# H616 register map
Vendor: Allwinner; Series: H616; File version: 0.1
CPU: other 0, little endian, MPU, no FPU, 0 interrupt priority bits
Registers are 32-bit, read-write, reset 0x0 unless marked. A register's access mark holds for its fields unless they carry their own. Offsets are from the block's base; [hi:lo] are bit positions; lines under a group give offsets from that group; {n}, {i} and the like mark numbered series; 'fields as' and 'values as' point back to an identical list; <NAME> marks a mode.

## Audio_Codec
Base 0x05096000
0x00 ANALOG DOMAIN REGISTER group
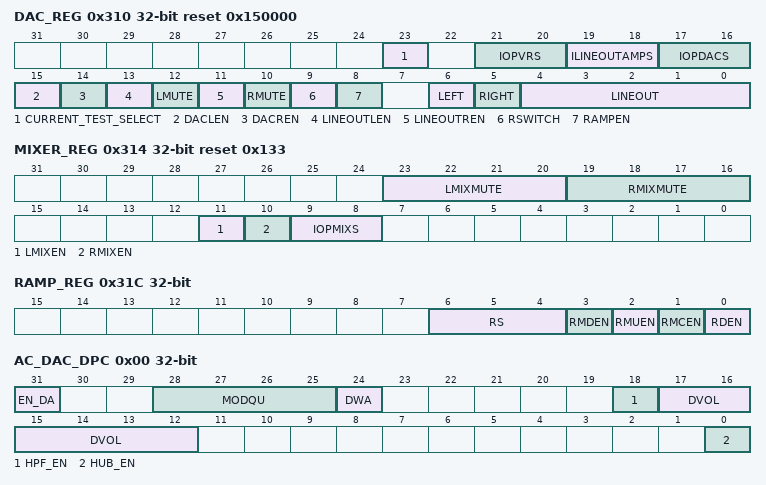
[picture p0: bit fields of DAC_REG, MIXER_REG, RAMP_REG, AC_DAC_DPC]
  0x310 DAC_REG reset 0x150000 — DAC Analog Control Register
    [23] CURRENT_TEST_SELECT — Internal Current Sink Test Enable 0: Normal 1: For Debug
      0=Normal; 1=For (For Debug)
    [21:20] IOPVRS — VRA2 Buffer OP Bias Current Select 00: 6uA 01: 7uA 10: 8uA 11: 9uA
      {v}=_{v+6}uA (v=0..3)
    [19:18] ILINEOUTAMPS — LINEOUTL/R AMP Bias Current Select 00: 6uA 01: 7uA 10: 8uA 11: 9uA
      {v}=_{v+6}uA (v=0..3)
    [17:16] IOPDACS — OPDAC Bias Current Select 00: 7uA 01: 8uA 10: 9uA 11: 10uA
      {v}=_{v+7}uA (v=0..3)
    [15] DACLEN — DACL Enable 0: Disable 1: Enable
      0=Disable; 1=Enable
    [14] DACREN — DACR Enable 0: Disable 1: Enable
      0=Disable; 1=Enable
    [13] LINEOUTLEN — Left Channel LINEOUT Enable 0: Disable 1: Enable
      0=Disable; 1=Enable
    [12] LMUTE — Left MIXER to Left Channel LINEOUT Mute Control 0: Mute 1: Not mute
      0=Mute; 1=Not_mute
    [11] LINEOUTREN — Right Channel LINEOUT Enable 0: Disable 1: Enable
      0=Disable; 1=Enable
    [10] RMUTE — Right MIXER to Right Channel LINEOUT Mute Control 0: Mute 1: Not mute
      0=Mute; 1=Not_mute
    [9] RSWITCH — 0: OUTPUT of RAMP_DAC 1: VRA1
      0=OUTPUT (OUTPUT of RAMP_DAC); 1=VRA1
    [8] RAMPEN — Ramp DAC Enable 0: Disable 1: Enable
      0=Disable; 1=Enable
    [6] LEFT — Left LIENOUT Source Select 0: Left Output Mixer 1: Left Output Mixer + Right Output Mixer
    [5] RIGHT — Right LIENOUT Source Select 0: Right Output Mixer 1: Left LINEOUT, for Differential Output
      0=Right Output Mixer; 1=Left LINEOUT, for Differential Output
    [4:0] LINEOUT — Volume Control, Total 30 level from 0x1F to 0x02 with the volume 0dB to -43.5dB, -1.5dB/step, mute when 00000 & 00001.
  0x314 MIXER_REG reset 0x133 — MIXER Analog Control Register
    [23:20] LMIXMUTE — Left Output Mixer Mute Control 0:Mute, 1:Not Mute Bit 23: Reserved Bit 22: Reserved Bit 21: Left Channel DAC Bit 20: Right Channel DAC
    [19:16] RMIXMUTE — Right Output Mixer Mute Control 0:Mute, 1:Not Mute Bit 19: Reserved Bit 18: Reserved Bit 17: Right Channel DAC Bit 16: Left Channel DAC
    [11] LMIXEN — Left Analog Output Mixer Enable 0: Disable 1: Enable
      0=Disable; 1=Enable
    [10] RMIXEN — Right Analog Output Mixer Enable 0: Disable 1: Enable
      0=Disable; 1=Enable
    [9:8] IOPMIXS — OPMIX/OPLPF Bias Current Select 00: 6uA 01: 7uA 10: 8uA 11: 9uA
      {v}=_{v+6}uA (v=0..3)
  0x31C RAMP_REG — RAMP Control Register
    [6:4] RS — Ramp Step 000: 3us 001: 6us 010: 12us 011: 24us 100: 48us 101: 60us 110: 96us 111: 120us
      0=_3us; 1=_6us; 2=_12us; 3=_24us; 4=_48us; 5=_60us; 6=_96us; 7=_120us
    [3] RMDEN — Ramp Manual Down Enable 0: Disable 1: Enable
      0=Disable; 1=Enable
    [2] RMUEN — Ramp Manual Up Enable 0: Disable 1: Enable
      0=Disable; 1=Enable
    [1] RMCEN — Ramp Manual Control Enable 0: Disable 1: Enable
      0=Disable; 1=Enable
    [0] RDEN — Ramp Digital Enable 0: Disable 1: Enable
      0=Disable; 1=Enable
0x00 AUDIO CODEC group
  0x00 AC_DAC_DPC — DAC Digital Part Control Register
    [31] EN_DA — DAC Digital Part Enable 0: Disable 1: Enable
      0=Disable; 1=Enable
    [28:25] MODQU — Internal DAC Quantization Levels Levels=[7*(21+MODQU[3:0])]/128 Default levels=7*21/128=1.15
    [24] DWA — DWA Function Disable 0: Enable 1: Disable
      0=Enable; 1=Disable
    [18] HPF_EN — High Pass Filter Enable 0: Disable 1: Enable
      0=Disable; 1=Enable
    [17:12] DVOL — Digital volume control: DVC, ATT=DVC[5:0]*(-1.16dB) 64 steps, -1.16dB/step
    [0] HUB_EN — Audio Hub Enable 0: Disable 1: Enable
      0=Disable; 1=Enable
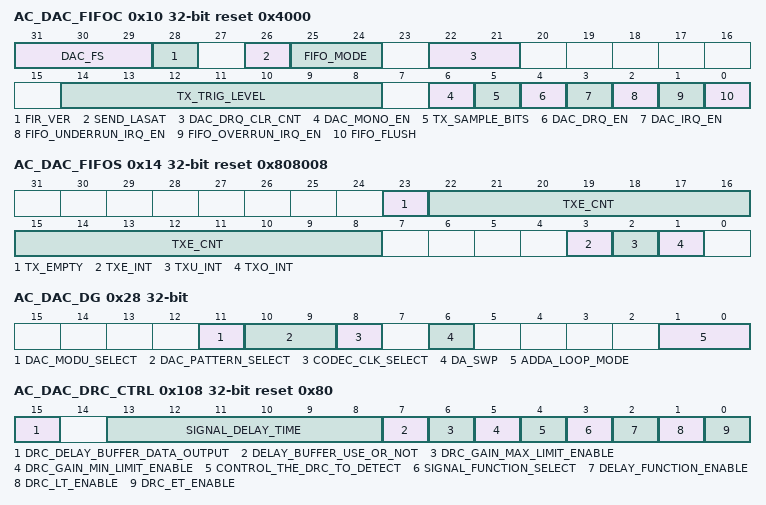
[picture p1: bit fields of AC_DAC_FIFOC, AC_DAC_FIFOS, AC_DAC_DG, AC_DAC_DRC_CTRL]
  0x10 AC_DAC_FIFOC reset 0x4000 — DAC FIFO Control Register
    [31:29] DAC_FS — Sample Rate of DAC 000: 48 kHz 010: 24 kHz 100: 12 kHz 110: 192 kHz 001: 32 kHz 011: 16 kHz 101: 8 kHz 111: 96 kHz 44.1 kHz/22.05 kHz/11.025 kHz can be supported by Audio PLL Configure Bit
      0=_48_kHz; 2=_24_kHz; 4=_12_kHz; 6=_192_kHz; 1=_32_kHz; 3=_16_kHz; 5=_8_kHz; 7=96 kHz 44.1 kHz/22.05 kHz/11.025 kHz can be supported by Audio PLL Configure Bit
    [28] FIR_VER — FIR Version 0: 64-Tap FIR 1: 32-Tap FIR
      0=_64_minus_Tap (64-Tap FIR); 1=_32_minus_Tap (32-Tap FIR)
    [26] SEND_LASAT — Audio sample select when TX FIFO underrun 0: Sending zero 1: Sending last audio sample
      0=Sending_zero; 1=Sending last audio sample
    [25:24] FIFO_MODE — For 20-bit transmitted audio sample: 00/10: FIFO_I[19:0] = {TXDATA[31:12]} 01/11: FIFO_I[19:0] = {TXDATA[19:0]} For 16-bit transmitted audio sample: 00/10: FIFO_I[19:0] = {TXDATA[31:16], 4`b0} 01/11: FIFO_I[19:0] = {TXDATA[15:0], 4`b0}
    [22:21] DAC_DRQ_CLR_CNT — When TX FIFO available room is less than or equal N, DRQ Request will be de-asserted. N is defined here: 00: IRQ/DRQ De-asserted when WLEVEL > TXTL 01: 4 10: 8 11: 16
      0=IRQ_slash_DRQ (IRQ/DRQ De-asserted when WLEVEL > TXTL); 1=_4; 2=_8; 3=_16
    [14:8] TX_TRIG_LEVEL — TX FIFO Empty Trigger Level (TXTL[12:0]) Interrupt and DMA request trigger level for TX FIFO normal condition. IRQ/DRQ generated when WLEVEL <= TXTL WLEVEL represents the number of valid samples in the TX FIFO.
    [6] DAC_MONO_EN — DAC Mono Enable 0: Stereo, 64 levels FIFO 1: mono, 128 levels FIFO When enabled, L & R channel send same data.
      0=Stereo, 64 levels FIFO; 1=mono, 128 levels FIFO When enabled, L & R channel send same data
    [5] TX_SAMPLE_BITS — Transmitting Audio Sample Resolution 0: 16 bits 1: 24 bits
      0=_16_bits; 1=_24_bits
    [4] DAC_DRQ_EN — DAC FIFO Empty DRQ Enable 0: Disable 1: Enable
      0=Disable; 1=Enable
    [3] DAC_IRQ_EN — DAC FIFO Empty IRQ Enable 0: Disable 1: Enable
      0=Disable; 1=Enable
    [2] FIFO_UNDERRUN_IRQ_EN — DAC FIFO Underrun IRQ Enable 0: Disable 1: Enable
      0=Disable; 1=Enable
    [1] FIFO_OVERRUN_IRQ_EN — DAC FIFO Overrun IRQ Enable 0: Disable 1: Enable
      0=Disable; 1=Enable
    [0] FIFO_FLUSH write-clears — DAC FIFO Flush Write `1` to flush TX FIFO, self clear to `0`
  0x14 AC_DAC_FIFOS reset 0x808008 — DAC FIFO Status Register
    [23] TX_EMPTY ro — TX FIFO Empty 0: No room for new sample in TX FIFO 1: More than one room for new sample in TX FIFO (>= 1 word)
      0=No room for new sample in TX FIFO; 1=More than one room for new sample in TX FIFO (>= 1 word)
    [22:8] TXE_CNT ro — TX FIFO Empty Space Word Counter
    [3] TXE_INT write-1-clears — TX FIFO Empty Pending Interrupt 0: No Pending IRQ 1: FIFO Empty Pending Interrupt Write `1` to clear this interrupt or automatically clear if interrupt condition fails.
      0=No Pending IRQ; 1=FIFO (FIFO Empty Pending Interrupt Write `1` to clear this interrupt or automatically clear if interrupt condition fails.)
    [2] TXU_INT write-1-clears — TX FIFO Underrun Pending Interrupt 0: No Pending Interrupt 1: FIFO Underrun Pending Interrupt Write `1` to clear this interrupt
      0=No Pending Interrupt; 1=FIFO (FIFO Underrun Pending Interrupt Write `1` to clear this interrupt)
    [1] TXO_INT write-1-clears — TX FIFO Overrun Pending Interrupt 0: No Pending Interrupt 1: FIFO Overrun Pending Interrupt Write `1` to clear this interrupt
      0=No Pending Interrupt; 1=FIFO (FIFO Overrun Pending Interrupt Write `1` to clear this interrupt)
  0x20 AC_DAC_TXDATA — DAC TX DATA Register
    [31:0] TX_DATA wo — Transmitting left, right channel sample data should be written this register one by one. The left channel sample data is first and then the right channel sample.
  0x24 AC_DAC_CNT — DAC TX FIFO Counter Register
    [31:0] TX_CNT — TX Sample Counter The audio sample number of sending into TXFIFO. When one sample is put into TXFIFO by DMA or by host IO, the TX sample counter register increases by one. The TX sample counter register can be set to any initial valve at any time. After been updated by the initial value, the counter register should count on base of this initial value.
  0x28 AC_DAC_DG — DAC Debug Register
    [11] DAC_MODU_SELECT — DAC Modulator Debug 0: DAC Modulator Normal Mode 1: DAC Modulator Debug Mode
      0=DAC Modulator Normal Mode; 1=DAC Modulator Debug Mode
    [10:9] DAC_PATTERN_SELECT — DAC Pattern Select 00: Normal (Audio Sample from TX FIFO) 01: -6 dB Sin wave 10: -60 dB Sin wave 11: Silent wave
      0=Normal (Audio Sample from TX FIFO); 1=_minus_6_dB (-6 dB Sin wave); 2=_minus_60_dB (-60 dB Sin wave); 3=Silent wave
    [8] CODEC_CLK_SELECT — CODEC Clock Source Select 0: CODEC Clock from PLL 1: CODEC Clock from OSC (for Debug)
      0=CODEC_Clock_from_PLL; 1=CODEC Clock from OSC (for Debug)
    [6] DA_SWP — DAC Output Channel Swap Enable 0:Disable 1:Enable
    [1:0] ADDA_LOOP_MODE — ADDA Loop Mode Select 00: Disable 01: ADDA LOOP MODE DACL/DACR connect to ADCL/ADCR 10: ADDA LOOP MODE DACL/DACR connect to ADCX/ADCY 11: Reserved
  0x100 AC_DAC_DRC_HHPFC reset 0xFF — DAC DRC High HPF Coef Register
    [10:0] HPF — coefficient setting and the data is 3.24 format.
  0x104 AC_DAC_DRC_LHPFC reset 0xFAC1 — DAC DRC Low HPF Coef Register
    [15:0] HPF — coefficient setting and the data is 3.24 format.
  0x108 AC_DAC_DRC_CTRL reset 0x80 — DAC DRC Control Register
    [15] DRC_DELAY_BUFFER_DATA_OUTPUT ro — DRC delay buffer data output state when drc delay function is enabled and the drc funciton is disabled. After disabled drc function and this bit goes to 0, the user should write the drc delay function bit to 0. 0: Not completed 1: Completed
      0=Not_completed; 1=Completed
    [13:8] SIGNAL_DELAY_TIME — Signal delay time setting 6'h00 : (8x1)fs 6'h01 : (8x2)fs 6'h02 : (8x3)fs ---------------------------------------- 6'h2e : (8*47)fs 6'h2f : (8*48)fs 6'h30 -- 6'h3f : (8*48)fs Delay time = 8*(n+1)fs, n<6'h30; When the delay function is disabled, the signal delay time is unused.
    [7] DELAY_BUFFER_USE_OR_NOT — The delay buffer use or not when the drc is disabled and the drc buffer data output completely. 0: Don't use the buffer 1: Use the buffer
      0=Don't use the buffer; 1=Use_the_buffer
    [6] DRC_GAIN_MAX_LIMIT_ENABLE — DRC gain max limit enable 0: Disable 1: Enable
      0=Disable; 1=Enable
    [5] DRC_GAIN_MIN_LIMIT_ENABLE — DRC gain min limit enable When this function is enabled, it will overwrite the noise detect funciton. 0: Disable 1: Enable
      0=Disable; 1=Enable
    [4] CONTROL_THE_DRC_TO_DETECT — Control the drc to detect noise when ET enable 0: Disable 1: Enable
      0=Disable; 1=Enable
    [3] SIGNAL_FUNCTION_SELECT — Signal function select 0: RMS filter 1: Peak filter When signal function selects Peak filter, the RMS parameter is unused. (AC_DRC_LRMSHAT/AC_DRC_LRMSLAT/AC_DRC_LRMSHAT/AC_DRC_LRMSLAT) When signal function selects RMS filter, the Peak filter parameter is unused.(AC_DRC_LPFHAT/AC_DRC_LPFLAT/AC_DRC_RPFHAT/AC_DRC_RPFLAT /AC_DRC_LPFHRT/AC_DRC_LPFLRT/AC_DRC_RPFHRT/AC_DRC_RPFLRT)
      0=RMS (RMS filter); 1=Peak filter When signal function selects Peak filter, the RMS parameter is unused. (AC_DRC_LRMSHAT/AC_DRC_LRMSLAT/AC_DRC_LRMSHAT/AC_DRC_LRMSLAT) When signal function selects RMS filter, the Peak filter parameter is unused.(AC_DRC_LPFHAT/AC_DRC_LPFLAT/AC_DRC_RPFHAT/AC_DRC_RPFLAT /AC_DRC_LPFHRT/AC_DRC_LPFLRT/AC_DRC_RPFHRT/AC_DRC_RPFLRT)
    [2] DELAY_FUNCTION_ENABLE — Delay function enable 0: Disable 1: Enable When the bit is disabled, the signal delay time is unused.
      0=Disable; 1=Enable When the bit is disabled, the signal delay time is unused
    [1] DRC_LT_ENABLE — DRC LT enable 0: Disable 1: Enable When the bit is disabled, Kl and OPL parameter is unused.
      0=Disable; 1=Enable When the bit is disabled, Kl and OPL parameter is unused
    [0] DRC_ET_ENABLE — DRC ET enable 0: Disable 1: Enable When the bit is disabled, Ke and OPE parameter is unused.
      0=Disable; 1=Enable When the bit is disabled, Ke and OPE parameter is unused
  0x10C AC_DAC_DRC_LPFHAT reset 0xB — DAC DRC Left Peak Filter High Attack Time Coef Register
    [10:0] LEFT_PEAK_FILTER_ATTACK_TIME — The left peak filter attack time parameter setting, which is determined by the equation that AT = 1-exp(-2.2Ts/ta). The format is 3.24.( The default value is 1ms)
  0x110 AC_DAC_DRC_LPFLAT reset 0x77BF — DAC DRC Left Peak Filter Low Attack Time Coef Register
    [15:0] LEFT_PEAK_FILTER_ATTACK_TIME — The left peak filter attack time parameter setting, which is determined by the equation that AT = 1-exp(-2.2Ts/ta). The format is 3.24.( The default value is 1ms)
  0x11C AC_DAC_DRC_LPFHRT reset 0xFF — DAC DRC Left Peak Filter High Release Time Coef Register
    [10:0] LEFT_PEAK_FILTER_RELEASE_TIME — The left peak filter release time parameter setting, which is determined by the equation that RT = exp(-2.2Ts/tr). The format is 3.24. (The default value is 100ms)
  0x120 AC_DAC_DRC_LPFLRT reset 0xE1F8 — DAC DRC Left Peak Filter Low Release Time Coef Register
    [15:0] LEFT_PEAK_FILTER_RELEASE_TIME — The left peak filter release time parameter setting, which is determined by the equation that RT = exp(-2.2Ts/tr). The format is 3.24. (The default value is 100ms)
  0x124 AC_DAC_DRC_RPFHRT reset 0xFF — DAC DRC Right Peak Filter High Release Time Coef Register
    [10:0] LEFT_PEAK_FILTER_ATTACK_TIME — The left peak filter attack time parameter setting, which determine by the equation that RT = exp(-2.2Ts/tr). The format is 3.24. (The default value is 100ms)
  0x128 AC_DAC_DRC_RPFLRT reset 0xE1F8 — DAC DRC Right Peak Filter Low Release Time Coef Register
    [15:0] LEFT_PEAK_FILTER_RELEASE_TIME — The left peak filter release time parameter setting, which determine by the equation that AT = exp(-2.2Ts/tr). The format is 3.24. (The default value is 100ms)
  0x12C AC_DAC_DRC_LRMSHAT reset 0x1 — DAC DRC Left RMS Filter High Coef Register
    [10:0] LEFT_RMS_FILTER_AVERAGE_TIME — The left RMS filter average time parameter setting, which is determined by the equation that AT = 1-exp(-2.2Ts/tav). The format is 3.24. (The default value is 10ms)
  0x130 AC_DAC_DRC_LRMSLAT reset 0x2BAF — DAC DRC Left RMS Filter Low Coef Register
    [15:0] LEFT_RMS_FILTER_AVERAGE_TIME — The left RMS filter average time parameter setting, which is determined by the equation that AT = 1-exp(-2.2Ts/tav). The format is 3.24. (The default value is 10ms)
  0x134 AC_DAC_DRC_RRMSHAT reset 0x1 — DAC DRC Right RMS Filter High Coef Register
    [10:0] RIGHT_RMS_FILTER_AVERAGE_TIME — The right RMS filter average time parameter setting, which determine by the equation that AT = 1-exp(-2.2Ts/tav). The format is 3.24.(The default value is 10ms)
  0x138 AC_DAC_DRC_RRMSLAT reset 0x2BAF — DAC DRC Right RMS Filter Low Coef Register
    [15:0] RIGHT_RMS_FILTER_AVERAGE_TIME — The right RMS filter average time parameter setting, which determine by the equation that AT = 1-exp(-2.2Ts/tav). The format is 3.24.(10ms)
  0x13C AC_DAC_DRC_HCT reset 0x6A4 — DAC DRC Compressor Threshold High Setting Register
    [15:0] COMPRESSOR_THRESHOLD — The compressor threshold setting, which is set by the equation that CTin = -CT/6.0206. The format is 8.24 (The default value is -40dB)
  0x140 AC_DAC_DRC_LCT reset 0xD3C0 — DAC DRC Compressor Slope High Setting Register
    fields as AUDIO.AC_DAC_DRC_HCT
  0x144 AC_DAC_DRC_HKC reset 0x80 — DAC DRC Compressor Slope High Setting Register
    [15:0] COMPRESSOR_SLOPE — The slope of the compressor, which is determined by the equation that Kc = 1/R, there, R is the ratio of the compressor, which always is interger. The format is 8.24. (The default value is 2 : 1)
  0x148 AC_DAC_DRC_LKC — DAC DRC Compressor Slope Low Setting Register
    fields as AUDIO.AC_DAC_DRC_HKC
  0x14C AC_DAC_DRC_HOPC reset 0xF95B — DAC DRC Compressor High Output at Compressor Threshold Register
    [15:0] COMPRESSOR_OUTPUT — The output of the compressor, which is determined by the equation -OPC/6.0206. The format is 8.24 (The default value is -40dB)
  0x150 AC_DAC_DRC_LOPC reset 0x2C3F — DAC DRC Compressor Low Output at Compressor Threshold Register
    [15:0] COMPRESSOR_OUTPUT — The output of the compressor, which is determined by the equation OPC/6.0206. The format is 8.24 (The default value is -40dB)
  0x154 AC_DAC_DRC_HLT reset 0x1A9 — DAC DRC Limiter Threshold High Setting Register
    [15:0] LIMITER_THRESHOLD — The limiter threshold setting, which is set by the equation that LTin = -LT/6.0206, The format is 8.24. (The default value is -10dB)
  0x158 AC_DAC_DRC_LLT reset 0x34F0 — DAC DRC Limiter Threshold Low Setting Register
    [15:0] LIMITER_THRESHOLD — The limiter threshold setting, which is set by the equation that LTin = -LT/6.0206. The format is 8.24. (The default value is -10dB)
  0x15C AC_DAC_DRC_HKl reset 0x5 — DAC DRC Limiter Slope High Setting Register
    [15:0] LIMITER_SLOPE — The slope of the limiter, which is determined by the equation that Kl = 1/R, there, R is the ratio of the limiter, which always is interger. The format is 8.24. (The default value is <50 :1>)
  0x160 AC_DAC_DRC_LKl reset 0x1EB8 — DAC DRC Limiter Slope Low Setting Register
    fields as AUDIO.AC_DAC_DRC_HKl
  0x164 AC_DAC_DRC_HOPL reset 0xFBD8 — DAC DRC Limiter High Output at Limiter Threshold
    [15:0] LIMITER_OUTPUT — The output of the limiter, which is determined by equation OPT/6.0206. The format is 8.24 (The default value is -25dB)
  0x168 AC_DAC_DRC_LOPL reset 0xFBA7 — DAC DRC Limiter Low Output at Limiter Threshold
    fields as AUDIO.AC_DAC_DRC_HOPL
  0x16C AC_DAC_DRC_HET reset 0xBA0 — DAC DRC Expander Threshold High Setting Register
    [15:0] EXPANDER_THRESHOLD — The expander threshold setting, which is set by the equation that ETin = -ET/6.0206, The format is 8.24. (The default value is -70dB)
  0x170 AC_DAC_DRC_LET reset 0x7291 — DAC DRC Expander Threshold Low Setting Register
    fields as AUDIO.AC_DAC_DRC_HET
  0x174 AC_DAC_DRC_HKE reset 0x500 — DAC DRC Expander Slope High Setting Register
    [13:0] EXPANDER_SLOPE — The slope of the expander, which is determined by the equation that Ke = 1/R, there, R is the ratio of the expander, which always is interger and the ke must larger than 50. The format is 8.24. (The default value is <1:5>)
  0x178 AC_DAC_DRC_LKE — DAC DRC Expander Slope Low Setting Register
    [15:0] EXPANDER_SLOPE — The slope of the expander, which is determined by the equation that Ke = 1/R, there, R is the ratio of the expander, which always is interger and the ke must larger than 50. The format is 8.24. (The default value is <1:5>)
  0x17C AC_DAC_DRC_HOPE reset 0xF45F — DAC DRC Expander High Output at Expander Threshold
    [15:0] EXPANDER_OUTPUT — The output of the expander, which is determined by equation OPE/6.0206. The format is 8.24 (The default value is -70dB)
  0x180 AC_DAC_DRC_LOPE reset 0x8D6E — DAC DRC Expander Low Output at Expander Threshold
    fields as AUDIO.AC_DAC_DRC_HOPE
  0x184 AC_DAC_DRC_HKN reset 0x100 — DAC DRC Linear Slope High Setting Register
    [15:0] LINEAR_SLOPE — The slope of the linear, which is determined by the equation that Kn = 1/R, there, R is the ratio of the linear, which always is interger . The format is 8.24. (The default value is <1:1>)
  0x188 AC_DAC_DRC_LKN — DAC DRC Linear Slope Low Setting Register
    fields as AUDIO.AC_DAC_DRC_HKN
  0x18C AC_DAC_DRC_SFHAT reset 0x2 — DAC DRC Smooth Filter Gain High Attack Time Coef Register
    [10:0] SMOOTH_FILTER_ATTACK_TIME — The smooth filter attack time parameter setting, which is determined by the equation that AT = 1-exp(-2.2Ts/tr). The format is 3.24. (The default value is 5ms)
  0x190 AC_DAC_DRC_SFLAT reset 0x5600 — DAC DRC Smooth Filter Gain Low Attack Time Coef Register
    [15:0] SMOOTH_FILTER_ATTACK_TIME — The smooth filter attack time parameter setting, which is determined by the equation that AT = 1-exp(-2.2Ts/tr). The format is 3.24. (The default value is 5ms)
  0x194 AC_DAC_DRC_SFHRT — DAC DRC Smooth Filter Gain High Release Time Coef Register
    [10:0] GAIN_SMOOTH_FILTER_RELEASE_TIME — The gain smooth filter release time parameter setting, which is determined by the equation that RT = 1-exp(-2.2Ts/tr). The format is 3.24. (The default value is 200ms)
  0x198 AC_DAC_DRC_SFLRT reset 0xF04 — DAC DRC Smooth Filter Gain Low Release Time Coef Register
    [15:0] GAIN_SMOOTH_FILTER_RELEASE_TIME — The gain smooth filter release time parameter setting, which is determined by the equation that RT = 1-exp(-2.2Ts/tr). The format is 3.24. (The default value is 200ms)
  0x19C AC_DAC_DRC_MXGHS reset 0xFE56 — DAC DRC MAX Gain High Setting Register
    [15:0] MAX_GAIN — The max gain setting, which is determined by equation MXG/6.0206. The format is 8.24 and must -20dB <MXG< 30dB (The default value is -10dB)
  0x1A0 AC_DAC_DRC_MXGLS reset 0xCB0F — DAC DRC MAX Gain Low Setting Register
    [15:0] MAX_GAIN — The max gain setting, which is determined by equation MXG/6.0206. The format is 8.24 and must -20dB <MXG < 30dB (The default value is -10dB)
  0x1A4 AC_DAC_DRC_MNGHS reset 0xF95B — DAC DRC MIN Gain High Setting Register
    [15:0] MIN_GAIN — The min gain setting, which is determined by equation MXG/6.0206. The format is 8.24 and must -60dB <=MNG <= -40dB (The default value is -40dB)
  0x1A8 AC_DAC_DRC_MNGLS reset 0x2C3F — DAC DRC MIN Gain Low Setting Register
    [15:0] MIN_GAIN — The min gain setting, which is determined by equation MNG/6.0206. The format is 8.24 and must -60dB <=MNG <= -40dB (The default value is -40dB)
  0x1AC AC_DAC_DRC_EPSHC — DAC DRC Expander Smooth Time High Coef Register
    [10:0] GAIN_SMOOTH_FILTER_RELEASE — The gain smooth filter release and attack time parameter setting in expander region, which are determined by the equation that RT = 1-exp(-2.2Ts/tr). The format is 3.24. (The default value is 30ms)
  0x1B0 AC_DAC_DRC_EPSLC reset 0x640C — DAC DRC Expander Smooth Time Low Coef Register
    [15:0] GAIN_SMOOTH_FILTER_RELEASE — The gain smooth filter release and attack time parameter setting in expander region, which are determined by the equation that RT = 1-exp(-2.2Ts/tr). The format is 3.24. (The default value is 30ms)
  0x1B8 AC_DAC_DRC_HPFHGAIN reset 0x100 — DAC DRC HPF Gain High Coef Register
    [10:0] HPF_COEFFICIENT_GAIN — The gain of the hpf coefficient setting which format is 3.24.(gain = 1)
  0x1BC AC_DAC_DRC_HPFLGAIN — DAC DRC HPF Gain Low Coef Register
    [15:0] HPF_COEFFICIENT_GAIN — The gain of the hpf coefficient setting which format is 3.24.(gain = 1)
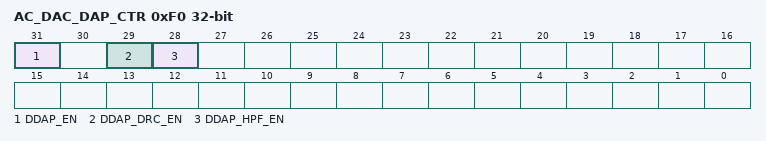
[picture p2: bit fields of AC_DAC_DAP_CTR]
0xF0 AC_DAC_DAP_CTR
  [31] DDAP_EN — DAP for DRC Enable 0: Bypass 1: Enable
    0=Bypass; 1=Enable
  [29] DDAP_DRC_EN — DRC enable control 0: Disable 1: Enable
    0=Disable; 1=Enable
  [28] DDAP_HPF_EN — HPF enable control 0: Disable 1: Enable
    0=Disable; 1=Enable
0x118 AC_DAC_DRC_RPFLAT reset 0x77BF
  [15:0] LEFT_PEAK_FILTER_ATTACK_TIME — The left peak filter attack time parameter setting, which is determined by the equation that AT = 1-exp(-2.2Ts/ta). The format is 3.24. (The default value is 1ms)
